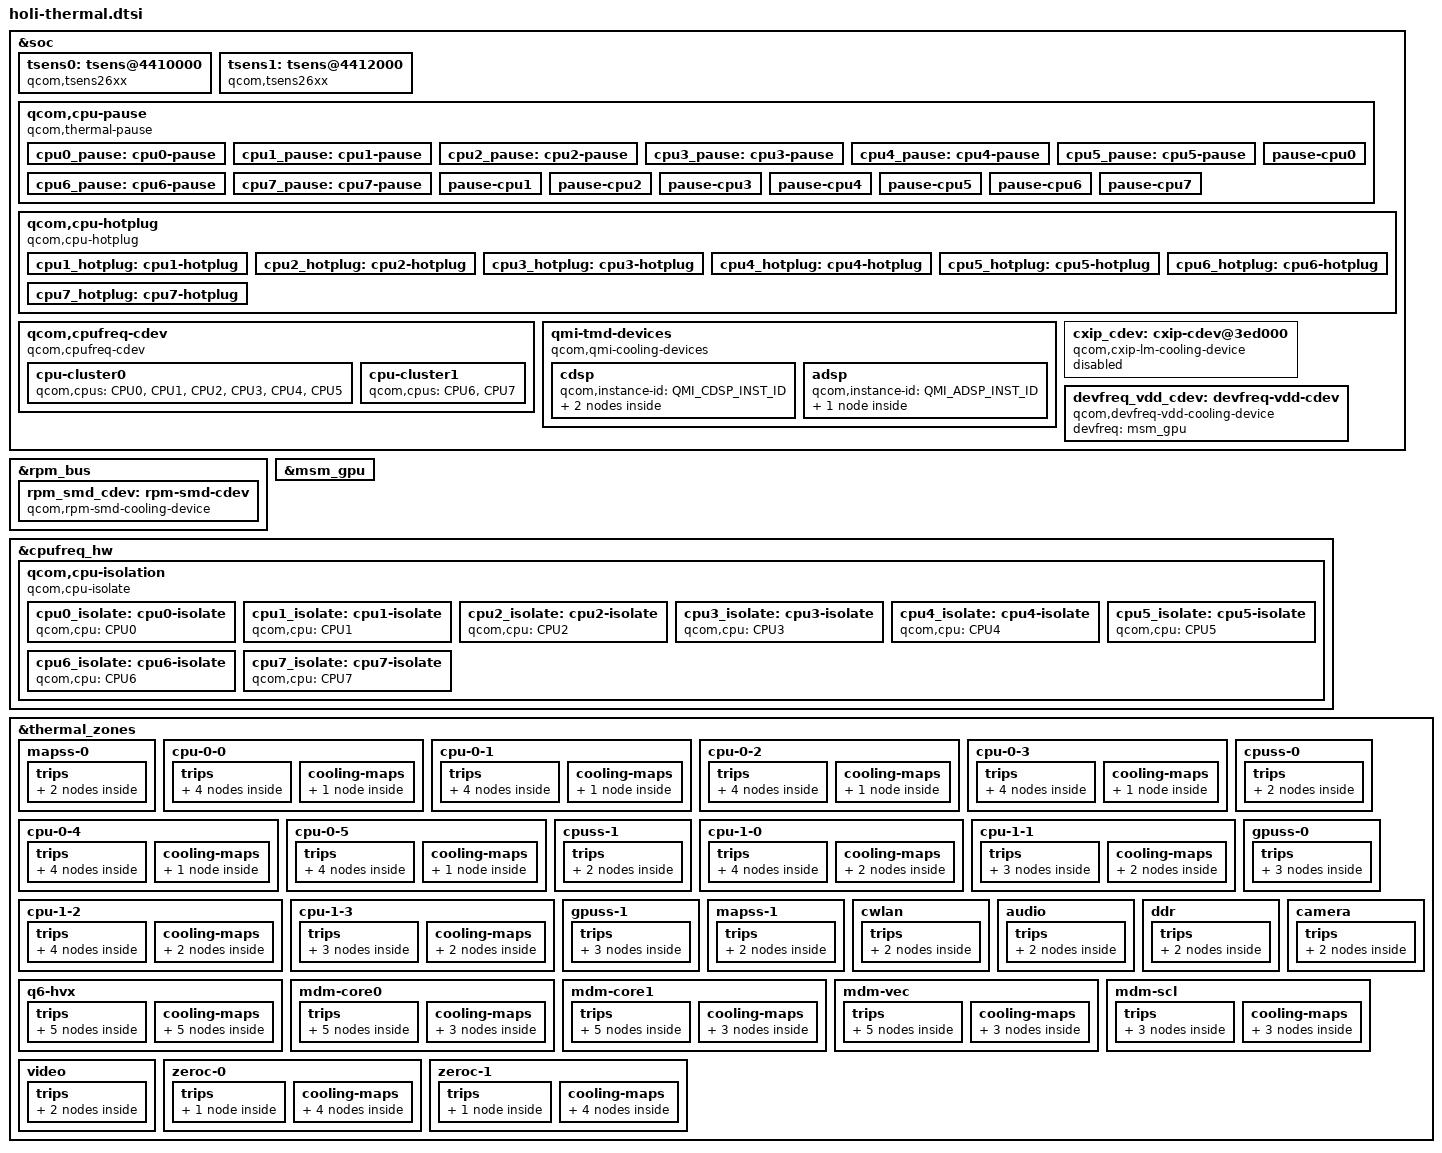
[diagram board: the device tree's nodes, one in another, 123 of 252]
#include <dt-bindings/thermal/thermal_qti.h>
#include "holi-thermal-modem.dtsi"

&soc {
	tsens0:tsens@4410000 {
		compatible = "qcom,tsens26xx";
		reg = <0x04410000 0x20>,
			<0x04411000 0x140>;
		reg-names = "tsens_srot_physical",
			"tsens_tm_physical";
		interrupts-extended = <&intc 0 275 IRQ_TYPE_LEVEL_HIGH>,
				<&intc 0 190 IRQ_TYPE_LEVEL_HIGH>,
				<&mpm 89 IRQ_TYPE_EDGE_RISING>;
		interrupt-names = "tsens-upper-lower",
				"tsens-critical",
				"tsens-0C";
		tsens-reinit-wa;
		0C-sensor-num = <16>;
		#thermal-sensor-cells = <1>;
	};

	tsens1:tsens@4412000 {
		compatible = "qcom,tsens26xx";
		reg = <0x04412000 0x20>,
			<0x04413000 0x140>;
		reg-names = "tsens_srot_physical",
			"tsens_tm_physical";
		interrupts-extended = <&intc 0 293 IRQ_TYPE_LEVEL_HIGH>,
				<&intc 0 316 IRQ_TYPE_LEVEL_HIGH>,
				<&mpm 90 IRQ_TYPE_EDGE_RISING>;
		interrupt-names = "tsens-upper-lower",
				"tsens-critical",
				"tsens-0C";
		tsens-reinit-wa;
		0C-sensor-num = <16>;
		#thermal-sensor-cells = <1>;
	};

	qcom,cpu-pause {
		compatible = "qcom,thermal-pause";

		cpu0_pause: cpu0-pause {
			qcom,cpus = <&CPU0>;
			qcom,cdev-alias = "thermal-pause-1";
			#cooling-cells = <2>;
		};

		cpu1_pause: cpu1-pause {
			qcom,cpus = <&CPU1>;
			qcom,cdev-alias = "thermal-pause-2";
			#cooling-cells = <2>;
		};

		cpu2_pause: cpu2-pause {
			qcom,cpus = <&CPU2>;
			qcom,cdev-alias = "thermal-pause-4";
			#cooling-cells = <2>;
		};

		cpu3_pause: cpu3-pause {
			qcom,cpus = <&CPU3>;
			qcom,cdev-alias = "thermal-pause-8";
			#cooling-cells = <2>;
		};

		cpu4_pause: cpu4-pause {
			qcom,cpus = <&CPU4>;
			qcom,cdev-alias = "thermal-pause-10";
			#cooling-cells = <2>;
		};

		cpu5_pause: cpu5-pause {
			qcom,cpus = <&CPU5>;
			qcom,cdev-alias = "thermal-pause-20";
			#cooling-cells = <2>;
		};

		cpu6_pause: cpu6-pause {
			qcom,cpus = <&CPU6>;
			qcom,cdev-alias = "thermal-pause-40";
			#cooling-cells = <2>;
		};

		cpu7_pause: cpu7-pause {
			qcom,cpus = <&CPU7>;
			qcom,cdev-alias = "thermal-pause-80";
			#cooling-cells = <2>;
		};

		/* Thermal-engine cooling devices */
		pause-cpu0 {
			qcom,cpus = <&CPU0>;
			qcom,cdev-alias = "pause-cpu0";
		};

		pause-cpu1 {
			qcom,cpus = <&CPU1>;
			qcom,cdev-alias = "pause-cpu1";
		};

		pause-cpu2 {
			qcom,cpus = <&CPU2>;
			qcom,cdev-alias = "pause-cpu2";
		};

		pause-cpu3 {
			qcom,cpus = <&CPU3>;
			qcom,cdev-alias = "pause-cpu3";
		};

		pause-cpu4 {
			qcom,cpus = <&CPU4>;
			qcom,cdev-alias = "pause-cpu4";
		};

		pause-cpu5 {
			qcom,cpus = <&CPU5>;
			qcom,cdev-alias = "pause-cpu5";
		};

		pause-cpu6 {
			qcom,cpus = <&CPU6>;
			qcom,cdev-alias = "pause-cpu6";
		};

		pause-cpu7 {
			qcom,cpus = <&CPU7>;
			qcom,cdev-alias = "pause-cpu7";
		};
	};

	qcom,cpu-hotplug {
		compatible = "qcom,cpu-hotplug";

		cpu1_hotplug: cpu1-hotplug {
			qcom,cpu = <&CPU1>;
			qcom,cdev-alias = "cpu-hotplug1";
			#cooling-cells = <2>;
		};

		cpu2_hotplug: cpu2-hotplug {
			qcom,cpu = <&CPU2>;
			qcom,cdev-alias = "cpu-hotplug2";
			#cooling-cells = <2>;
		};

		cpu3_hotplug: cpu3-hotplug {
			qcom,cpu = <&CPU3>;
			qcom,cdev-alias = "cpu-hotplug3";
			#cooling-cells = <2>;
		};

		cpu4_hotplug: cpu4-hotplug {
			qcom,cpu = <&CPU4>;
			qcom,cdev-alias = "cpu-hotplug4";
			#cooling-cells = <2>;
		};

		cpu5_hotplug: cpu5-hotplug {
			qcom,cpu = <&CPU5>;
			qcom,cdev-alias = "cpu-hotplug5";
			#cooling-cells = <2>;
		};

		cpu6_hotplug: cpu6-hotplug {
			qcom,cpu = <&CPU6>;
			qcom,cdev-alias = "cpu-hotplug6";
			#cooling-cells = <2>;
		};

		cpu7_hotplug: cpu7-hotplug {
			qcom,cpu = <&CPU7>;
			qcom,cdev-alias = "cpu-hotplug7";
			#cooling-cells = <2>;
		};
	};

	qcom,cpufreq-cdev {
		compatible = "qcom,cpufreq-cdev";

		cpu-cluster0 {
			qcom,cpus = <&CPU0 &CPU1 &CPU2 &CPU3 &CPU4 &CPU5>;
		};

		cpu-cluster1 {
			qcom,cpus = <&CPU6 &CPU7>;
		};
	};

	qmi-tmd-devices {
		compatible = "qcom,qmi-cooling-devices";

		cdsp {
			qcom,instance-id = <QMI_CDSP_INST_ID>;

			cdsp_sw: cdsp {
				qcom,qmi-dev-name = "cdsp_sw";
				#cooling-cells = <2>;
			};

			cdsp_hw: cdsp_hw {
				qcom,qmi-dev-name = "cdsp_hw";
				#cooling-cells = <2>;
			};
		};

		adsp {
			qcom,instance-id = <QMI_ADSP_INST_ID>;

			adsp_vdd: adsp_vdd {
				qcom,qmi-dev-name = "cpuv_restriction_cold";
				#cooling-cells = <2>;
			};
		};
	};

	cxip_cdev: cxip-cdev@3ed000 {
		compatible = "qcom,cxip-lm-cooling-device";
		reg = <0x3ed000 0xe008>;
		qcom,thermal-client-offset = <0x8000>;
		/* 4th and 5th offsets to bypass VICTIM1 */
		qcom,bypass-client-list = <0x2004 0x4004 0x6004 0xc004 0xc008 0xe004>;
		#cooling-cells = <2>;
		status = "disabled";
	};

	devfreq_vdd_cdev: devfreq-vdd-cdev {
		compatible = "qcom,devfreq-vdd-cooling-device";
		devfreq = <&msm_gpu>;
		#cooling-cells = <2>;
	};

};

&rpm_bus {
	rpm_smd_cdev: rpm-smd-cdev {
		compatible = "qcom,rpm-smd-cooling-device";
		#cooling-cells = <2>;
	};
};

&msm_gpu {
	#cooling-cells = <2>;
};

&cpufreq_hw {
	qcom,cpu-isolation {
		compatible = "qcom,cpu-isolate";

		cpu0_isolate: cpu0-isolate {
			qcom,cpu = <&CPU0>;
			#cooling-cells = <2>;
		};

		cpu1_isolate: cpu1-isolate {
			qcom,cpu = <&CPU1>;
			#cooling-cells = <2>;
		};

		cpu2_isolate: cpu2-isolate {
			qcom,cpu = <&CPU2>;
			#cooling-cells = <2>;
		};

		cpu3_isolate: cpu3-isolate {
			qcom,cpu = <&CPU3>;
			#cooling-cells = <2>;
		};

		cpu4_isolate: cpu4-isolate {
			qcom,cpu = <&CPU4>;
			#cooling-cells = <2>;
		};

		cpu5_isolate: cpu5-isolate {
			qcom,cpu = <&CPU5>;
			#cooling-cells = <2>;
		};

		cpu6_isolate: cpu6-isolate {
			qcom,cpu = <&CPU6>;
			#cooling-cells = <2>;
		};

		cpu7_isolate: cpu7-isolate {
			qcom,cpu = <&CPU7>;
			#cooling-cells = <2>;
		};
	};
};

#include "holi-thermal-modem.dtsi"

&thermal_zones {
	mapss-0 {
		polling-delay-passive = <0>;
		polling-delay = <0>;
		thermal-sensors = <&tsens0 0>;
		trips {
			active-config0 {
				temperature = <125000>;
				hysteresis = <1000>;
				type = "passive";
			};

			reset-mon-cfg {
				temperature = <115000>;
				hysteresis = <5000>;
				type = "passive";
			};
		};
	};

	cpu-0-0 {
		polling-delay-passive = <0>;
		polling-delay = <0>;
		thermal-sensors = <&tsens0 1>;
		trips {
			active-config0 {
				temperature = <125000>;
				hysteresis = <1000>;
				type = "passive";
			};

			thermal-hal-config {
				temperature = <125000>;
				hysteresis = <1000>;
				type = "passive";
			};

			reset-mon-cfg {
				temperature = <115000>;
				hysteresis = <5000>;
				type = "passive";
			};

			cpu00_config: cpu00-config {
				temperature = <110000>;
				hysteresis = <10000>;
				type = "passive";
			};
		};

		cooling-maps {
			cpu00_cdev {
				trip = <&cpu00_config>;
				cooling-device = <&cpu0_pause 1 1>;
			};
		};
	};

	cpu-0-1 {
		polling-delay-passive = <0>;
		polling-delay = <0>;
		thermal-sensors = <&tsens0 2>;
		trips {
			active-config0 {
				temperature = <125000>;
				hysteresis = <1000>;
				type = "passive";
			};

			thermal-hal-config {
				temperature = <125000>;
				hysteresis = <1000>;
				type = "passive";
			};

			reset-mon-cfg {
				temperature = <115000>;
				hysteresis = <5000>;
				type = "passive";
			};

			cpu01_config: cpu01-config {
				temperature = <110000>;
				hysteresis = <10000>;
				type = "passive";
			};
		};

		cooling-maps {
			cpu01_cdev {
				trip = <&cpu01_config>;
				cooling-device = <&cpu1_pause 1 1>;
			};
		};
	};

	cpu-0-2 {
		polling-delay-passive = <0>;
		polling-delay = <0>;
		thermal-sensors = <&tsens0 3>;
		trips {
			active-config0 {
				temperature = <125000>;
				hysteresis = <1000>;
				type = "passive";
			};

			thermal-hal-config {
				temperature = <125000>;
				hysteresis = <1000>;
				type = "passive";
			};

			reset-mon-cfg {
				temperature = <115000>;
				hysteresis = <5000>;
				type = "passive";
			};

			cpu02_config: cpu02-config {
				temperature = <110000>;
				hysteresis = <10000>;
				type = "passive";
			};
		};

		cooling-maps {
			cpu02_cdev {
				trip = <&cpu02_config>;
				cooling-device = <&cpu2_pause 1 1>;
			};
		};
	};

	cpu-0-3 {
		polling-delay-passive = <0>;
		polling-delay = <0>;
		thermal-sensors = <&tsens0 4>;
		trips {
			active-config0 {
				temperature = <125000>;
				hysteresis = <1000>;
				type = "passive";
			};

			thermal-hal-config {
				temperature = <125000>;
				hysteresis = <1000>;
				type = "passive";
			};

			reset-mon-cfg {
				temperature = <115000>;
				hysteresis = <5000>;
				type = "passive";
			};

			cpu03_config: cpu03-config {
				temperature = <110000>;
				hysteresis = <10000>;
				type = "passive";
			};
		};

		cooling-maps {
			cpu03_cdev {
				trip = <&cpu03_config>;
				cooling-device = <&cpu3_pause 1 1>;
			};
		};
	};

	cpu-0-4 {
		polling-delay-passive = <0>;
		polling-delay = <0>;
		thermal-sensors = <&tsens0 5>;
		trips {
			active-config0 {
				temperature = <125000>;
				hysteresis = <1000>;
				type = "passive";
			};

			thermal-hal-config {
				temperature = <125000>;
				hysteresis = <1000>;
				type = "passive";
			};

			reset-mon-cfg {
				temperature = <115000>;
				hysteresis = <5000>;
				type = "passive";
			};

			cpu04_config: cpu04-config {
				temperature = <110000>;
				hysteresis = <10000>;
				type = "passive";
			};
		};

		cooling-maps {
			cpu04_cdev {
				trip = <&cpu04_config>;
				cooling-device = <&cpu4_pause 1 1>;
			};
		};
	};

	cpu-0-5 {
		polling-delay-passive = <0>;
		polling-delay = <0>;
		thermal-sensors = <&tsens0 6>;
		trips {
			active-config0 {
				temperature = <125000>;
				hysteresis = <1000>;
				type = "passive";
			};

			thermal-hal-config {
				temperature = <125000>;
				hysteresis = <1000>;
				type = "passive";
			};

			reset-mon-cfg {
				temperature = <115000>;
				hysteresis = <5000>;
				type = "passive";
			};

			cpu05_config: cpu05-config {
				temperature = <110000>;
				hysteresis = <10000>;
				type = "passive";
			};
		};

		cooling-maps {
			cpu05_cdev {
				trip = <&cpu05_config>;
				cooling-device = <&cpu5_pause 1 1>;
			};
		};
	};

	cpuss-0 {
		polling-delay-passive = <0>;
		polling-delay = <0>;
		thermal-sensors = <&tsens0 7>;
		trips {
			active-config0 {
				temperature = <125000>;
				hysteresis = <1000>;
				type = "passive";
			};

			reset-mon-cfg {
				temperature = <115000>;
				hysteresis = <5000>;
				type = "passive";
			};
		};
	};

	cpuss-1 {
		polling-delay-passive = <0>;
		polling-delay = <0>;
		thermal-sensors = <&tsens0 8>;
		trips {
			active-config0 {
				temperature = <125000>;
				hysteresis = <1000>;
				type = "passive";
			};

			reset-mon-cfg {
				temperature = <115000>;
				hysteresis = <5000>;
				type = "passive";
			};
		};
	};

	cpu-1-0 {
		polling-delay-passive = <0>;
		polling-delay = <0>;
		thermal-sensors = <&tsens0 9>;
		trips {
			active-config0 {
				temperature = <125000>;
				hysteresis = <1000>;
				type = "passive";
			};

			thermal-hal-config {
				temperature = <125000>;
				hysteresis = <1000>;
				type = "passive";
			};

			reset-mon-cfg {
				temperature = <115000>;
				hysteresis = <5000>;
				type = "passive";
			};

			cpu10_config: cpu10-config {
				temperature = <110000>;
				hysteresis = <10000>;
				type = "passive";
			};
		};

		cooling-maps {
			cpu10_cdev {
				trip = <&cpu10_config>;
				cooling-device = <&cpu6_pause 1 1>;
			};

			cpu10_cdev1 {
				trip = <&cpu10_config>;
				cooling-device = <&CPU6 7 7>;
			};
		};
	};

	cpu-1-1 {
		polling-delay-passive = <0>;
		polling-delay = <0>;
		thermal-sensors = <&tsens0 10>;
		trips {
			active-config0 {
				temperature = <125000>;
				hysteresis = <1000>;
				type = "passive";
			};

			reset-mon-cfg {
				temperature = <115000>;
				hysteresis = <5000>;
				type = "passive";
			};

			cpu11_config: cpu11-config {
				temperature = <110000>;
				hysteresis = <10000>;
				type = "passive";
			};
		};

		cooling-maps {
			cpu11_cdev {
				trip = <&cpu11_config>;
				cooling-device = <&cpu6_pause 1 1>;
			};

			cpu11_cdev1 {
				trip = <&cpu11_config>;
				cooling-device = <&CPU6 7 7>;
			};
		};
	};

	cpu-1-2 {
		polling-delay-passive = <0>;
		polling-delay = <0>;
		thermal-sensors = <&tsens0 11>;
		trips {
			active-config0 {
				temperature = <125000>;
				hysteresis = <1000>;
				type = "passive";
			};

			thermal-hal-config {
				temperature = <125000>;
				hysteresis = <1000>;
				type = "passive";
			};

			reset-mon-cfg {
				temperature = <115000>;
				hysteresis = <5000>;
				type = "passive";
			};

			cpu12_config: cpu12-config {
				temperature = <110000>;
				hysteresis = <10000>;
				type = "passive";
			};
		};

		cooling-maps {
			cpu12_cdev {
				trip = <&cpu12_config>;
				cooling-device = <&cpu7_pause 1 1>;
			};

			cpu12_cdev1 {
				trip = <&cpu12_config>;
				cooling-device = <&CPU6 7 7>;
			};
		};
	};

	cpu-1-3 {
		polling-delay-passive = <0>;
		polling-delay = <0>;
		thermal-sensors = <&tsens0 12>;
		trips {
			active-config0 {
				temperature = <125000>;
				hysteresis = <1000>;
				type = "passive";
			};

			reset-mon-cfg {
				temperature = <115000>;
				hysteresis = <5000>;
				type = "passive";
			};

			cpu13_config: cpu13-config {
				temperature = <110000>;
				hysteresis = <10000>;
				type = "passive";
			};
		};

		cooling-maps {
			cpu13_cdev {
				trip = <&cpu13_config>;
				cooling-device = <&cpu7_pause 1 1>;
			};

			cpu13_cdev1 {
				trip = <&cpu13_config>;
				cooling-device = <&CPU6 7 7>;
			};
		};
	};

	gpuss-0 {
		polling-delay-passive = <0>;
		polling-delay = <0>;
		thermal-sensors = <&tsens0 13>;
		trips {
			active-config0 {
				temperature = <125000>;
				hysteresis = <1000>;
				type = "passive";
			};

			thermal-hal-config {
				temperature = <125000>;
				hysteresis = <1000>;
				type = "passive";
			};

			reset-mon-cfg {
				temperature = <115000>;
				hysteresis = <5000>;
				type = "passive";
			};
		};
	};

	gpuss-1 {
		polling-delay-passive = <0>;
		polling-delay = <0>;
		thermal-sensors = <&tsens0 14>;
		trips {
			active-config0 {
				temperature = <125000>;
				hysteresis = <1000>;
				type = "passive";
			};

			thermal-hal-config {
				temperature = <125000>;
				hysteresis = <1000>;
				type = "passive";
			};

			reset-mon-cfg {
				temperature = <115000>;
				hysteresis = <5000>;
				type = "passive";
			};
		};
	};

	mapss-1 {
		polling-delay-passive = <0>;
		polling-delay = <0>;
		thermal-sensors = <&tsens1 0>;
		trips {
			active-config0 {
				temperature = <125000>;
				hysteresis = <1000>;
				type = "passive";
			};

			reset-mon-cfg {
				temperature = <115000>;
				hysteresis = <5000>;
				type = "passive";
			};
		};
	};

	cwlan {
		polling-delay-passive = <0>;
		polling-delay = <0>;
		thermal-sensors = <&tsens1 1>;
		trips {
			active-config0 {
				temperature = <125000>;
				hysteresis = <1000>;
				type = "passive";
			};

			reset-mon-cfg {
				temperature = <115000>;
				hysteresis = <5000>;
				type = "passive";
			};
		};
	};

	audio {
		polling-delay-passive = <0>;
		polling-delay = <0>;
		thermal-sensors = <&tsens1 2>;
		trips {
			active-config0 {
				temperature = <125000>;
				hysteresis = <1000>;
				type = "passive";
			};

			reset-mon-cfg {
				temperature = <115000>;
				hysteresis = <5000>;
				type = "passive";
			};
		};
	};

	ddr {
		polling-delay-passive = <0>;
		polling-delay = <0>;
		thermal-sensors = <&tsens1 3>;
		trips {
			active-config0 {
				temperature = <125000>;
				hysteresis = <1000>;
				type = "passive";
			};

			reset-mon-cfg {
				temperature = <115000>;
				hysteresis = <5000>;
				type = "passive";
			};
		};
	};

	q6-hvx {
		polling-delay-passive = <0>;
		polling-delay = <0>;
		thermal-sensors = <&tsens1 4>;
		trips {
			active-config0 {
				temperature = <125000>;
				hysteresis = <1000>;
				type = "passive";
			};

			reset-mon-cfg {
				temperature = <115000>;
				hysteresis = <5000>;
				type = "passive";
			};

			q6_hvx_trip0: q6-hvx-trip0 {
				temperature = <95000>;
				hysteresis = <0>;
				type = "passive";
			};

			q6_hvx_cxip: q6-hvx-cxip-trip {
				temperature = <95000>;
				hysteresis = <20000>;
				type = "passive";
			};

			q6_hvx_cx_mon: q6-hvx-cx-mon {
				temperature = <100000>;
				hysteresis = <5000>;
				type = "passive";
			};
		};

		cooling-maps {
			q6-hvx-cdev0 {
				trip = <&q6_hvx_trip0>;
				cooling-device = <&cdsp_sw THERMAL_NO_LIMIT
							THERMAL_NO_LIMIT>;
			};

			q6-hvx-cxip-cdev {
				trip = <&q6_hvx_cxip>;
				cooling-device = <&cxip_cdev 1 1>;
			};

			q6-hvx-cx-cdev0 {
				trip = <&q6_hvx_cx_mon>;
				/* throttle to 565000000Hz */
				cooling-device = <&msm_gpu 5 5>;
			};

			q6-hvx-cx-cdev1 {
				trip = <&q6_hvx_cx_mon>;
				cooling-device = <&modem_skin 3 3>;
			};

			q6-hvx-cx-cdev2 {
				trip = <&q6_hvx_cx_mon>;
				cooling-device = <&cdsp_sw 4 4>;
			};
		};
	};

	camera {
		polling-delay-passive = <0>;
		polling-delay = <0>;
		thermal-sensors = <&tsens1 5>;
		trips {
			active-config0 {
				temperature = <125000>;
				hysteresis = <1000>;
				type = "passive";
			};

			reset-mon-cfg {
				temperature = <115000>;
				hysteresis = <5000>;
				type = "passive";
			};
		};
	};

	mdm-core0 {
		polling-delay-passive = <0>;
		polling-delay = <0>;
		thermal-sensors = <&tsens1 6>;
		trips {
			active-config0 {
				temperature = <125000>;
				hysteresis = <1000>;
				type = "passive";
			};

			reset-mon-cfg {
				temperature = <115000>;
				hysteresis = <5000>;
				type = "passive";
			};

			mdmss0_trip0: mdmss0-trip0 {
				temperature = <95000>;
				hysteresis = <15000>;
				type = "passive";
			};

			mdmss0_trip1: mdmss0-trip1 {
				temperature = <105000>;
				hysteresis = <15000>;
				type = "passive";
			};

			mdmss0_trip2: mdmss0-trip2 {
				temperature = <115000>;
				hysteresis = <15000>;
				type = "passive";
			};
		};

		cooling-maps {
			mdmss0_cdev0 {
				trip = <&mdmss0_trip0>;
				cooling-device = <&modem_tj 1 1>;
			};

			mdmss0_cdev1 {
				trip = <&mdmss0_trip1>;
				cooling-device = <&modem_tj 2 2>;
			};

			mdmss0_cdev2 {
				trip = <&mdmss0_trip2>;
				cooling-device = <&modem_tj 3 3>;
			};
		};
	};

	mdm-core1 {
		polling-delay-passive = <0>;
		polling-delay = <0>;
		thermal-sensors = <&tsens1 7>;
		trips {
			active-config0 {
				temperature = <125000>;
				hysteresis = <1000>;
				type = "passive";
			};

			reset-mon-cfg {
				temperature = <115000>;
				hysteresis = <5000>;
				type = "passive";
			};

			mdmss1_trip0: mdmss1-trip0 {
				temperature = <95000>;
				hysteresis = <15000>;
				type = "passive";
			};

			mdmss1_trip1: mdmss1-trip1 {
				temperature = <105000>;
				hysteresis = <15000>;
				type = "passive";
			};

			mdmss1_trip2: mdmss1-trip2 {
				temperature = <115000>;
				hysteresis = <15000>;
				type = "passive";
			};
		};

		cooling-maps {
			mdmss1_cdev0 {
				trip = <&mdmss1_trip0>;
				cooling-device = <&modem_tj 1 1>;
			};

			mdmss1_cdev1 {
				trip = <&mdmss1_trip1>;
				cooling-device = <&modem_tj 2 2>;
			};

			mdmss1_cdev2 {
				trip = <&mdmss1_trip2>;
				cooling-device = <&modem_tj 3 3>;
			};
		};
	};

	mdm-vec {
		polling-delay-passive = <0>;
		polling-delay = <0>;
		thermal-sensors = <&tsens1 8>;
		trips {
			active-config0 {
				temperature = <125000>;
				hysteresis = <1000>;
				type = "passive";
			};

			reset-mon-cfg {
				temperature = <115000>;
				hysteresis = <5000>;
				type = "passive";
			};

			mdmss2_trip0: mdmss2-trip0 {
				temperature = <95000>;
				hysteresis = <15000>;
				type = "passive";
			};

			mdmss2_trip1: mdmss2-trip1 {
				temperature = <105000>;
				hysteresis = <15000>;
				type = "passive";
			};

			mdmss2_trip2: mdmss2-trip2 {
				temperature = <115000>;
				hysteresis = <15000>;
				type = "passive";
			};
		};

		cooling-maps {
			mdmss2_cdev0 {
				trip = <&mdmss2_trip0>;
				cooling-device = <&modem_tj 1 1>;
			};

			mdmss2_cdev1 {
				trip = <&mdmss2_trip1>;
				cooling-device = <&modem_tj 2 2>;
			};

			mdmss2_cdev2 {
				trip = <&mdmss2_trip2>;
				cooling-device = <&modem_tj 3 3>;
			};
		};
	};

	mdm-scl {
		polling-delay-passive = <0>;
		polling-delay = <0>;
		thermal-sensors = <&tsens1 9>;
		trips {
			mdmss3_trip0: mdmss3-trip0 {
				temperature = <95000>;
				hysteresis = <15000>;
				type = "passive";
			};

			mdmss3_trip1: mdmss3-trip1 {
				temperature = <105000>;
				hysteresis = <15000>;
				type = "passive";
			};

			mdmss3_trip2: mdmss3-trip2 {
				temperature = <115000>;
				hysteresis = <15000>;
				type = "passive";
			};
		};

		cooling-maps {
			mdmss3_cdev0 {
				trip = <&mdmss3_trip0>;
				cooling-device = <&modem_tj 1 1>;
			};

			mdmss3_cdev1 {
				trip = <&mdmss3_trip1>;
				cooling-device = <&modem_tj 2 2>;
			};

			mdmss3_cdev2 {
				trip = <&mdmss3_trip2>;
				cooling-device = <&modem_tj 3 3>;
			};
		};
	};

	video {
		polling-delay-passive = <0>;
		polling-delay = <0>;
		thermal-sensors = <&tsens1 10>;
		trips {
			active-config0 {
				temperature = <125000>;
				hysteresis = <1000>;
				type = "passive";
			};

			reset-mon-cfg {
				temperature = <115000>;
				hysteresis = <5000>;
				type = "passive";
			};
		};
	};

	zeroc-0 {
		polling-delay-passive = <0>;
		polling-delay = <0>;
		thermal-sensors = <&tsens0 16>;

		trips {
			zeroc_0_trip: active-config0 {
				temperature = <1>;
				hysteresis = <1>;
				type = "passive";
			};
		};

		cooling-maps {
			rpm_smd_cdev {
				trip = <&zeroc_0_trip>;
				cooling-device = <&rpm_smd_cdev 2 2>;
			};

			devfreq_vdd_cdev {
				trip = <&zeroc_0_trip>;
				cooling-device = <&devfreq_vdd_cdev 2 2>;
			};

			adsp_vdd_cdev {
				trip = <&zeroc_0_trip>;
				cooling-device = <&adsp_vdd 1 1>;
			};

			modem_vdd_cdev {
				trip = <&zeroc_0_trip>;
				cooling-device = <&modem_vdd 1 1>;
			};
		};
	};

	zeroc-1 {
		polling-delay-passive = <0>;
		polling-delay = <0>;
		thermal-sensors = <&tsens1 16>;

		trips {
			zeroc_1_trip: active-config0 {
				temperature = <1>;
				hysteresis = <1>;
				type = "passive";
			};
		};

		cooling-maps {
			rpm_smd_cdev {
				trip = <&zeroc_1_trip>;
				cooling-device = <&rpm_smd_cdev 2 2>;
			};

			devfreq_vdd_cdev {
				trip = <&zeroc_1_trip>;
				cooling-device = <&devfreq_vdd_cdev 2 2>;
			};

			adsp_vdd_cdev {
				trip = <&zeroc_1_trip>;
				cooling-device = <&adsp_vdd 1 1>;
			};

			modem_vdd_cdev {
				trip = <&zeroc_1_trip>;
				cooling-device = <&modem_vdd 1 1>;
			};
		};
	};
};

